VERSION ""

NS_ :

BS_:

BU_:
VAL_TABLE_ OnOff 1 "ON" 0 "OFF" ;

BO_ 1287 dbgGdStatus2: 4 Vector__XXX
 SG_ respNum : 16|16@1+ (1,0) [0|0] "" Vector__XXX
 SG_ reqNum : 0|16@1+ (1,0) [0|0] "" Vector__XXX

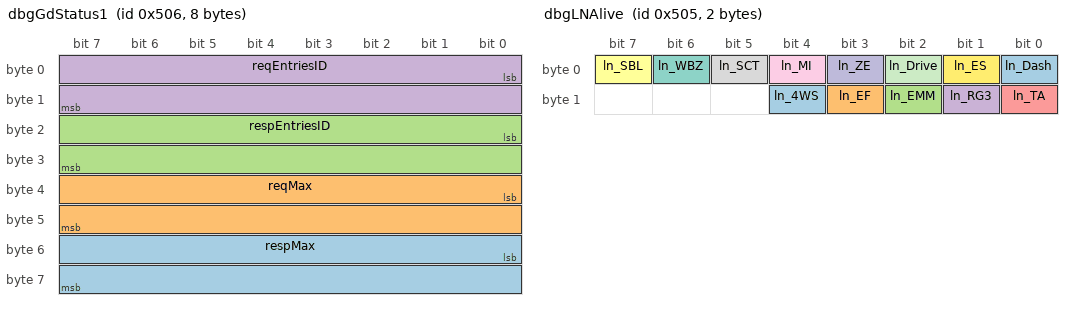
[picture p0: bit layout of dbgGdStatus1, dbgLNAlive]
BO_ 1286 dbgGdStatus1: 8 Vector__XXX
 SG_ respMax : 48|16@1+ (1,0) [0|0] "" Vector__XXX
 SG_ reqMax : 32|16@1+ (1,0) [0|0] "" Vector__XXX
 SG_ respEntriesID : 16|16@1+ (1,0) [0|0] "" Vector__XXX
 SG_ reqEntriesID : 0|16@1+ (1,0) [0|0] "" Vector__XXX

BO_ 291 dbgTime: 4 Vector__XXX
 SG_ keepAlive : 0|32@1+ (0.1,0) [0|0] "[s]" Vector__XXX

BO_ 1285 dbgLNAlive: 2 Vector__XXX
 SG_ ln_4WS : 12|1@1+ (1,0) [0|1] "" Vector__XXX
 SG_ ln_EF : 11|1@1+ (1,0) [0|1] "" Vector__XXX
 SG_ ln_EMM : 10|1@1+ (1,0) [0|1] "" Vector__XXX
 SG_ ln_RG3 : 9|1@1+ (1,0) [0|1] "" Vector__XXX
 SG_ ln_TA : 8|1@1+ (1,0) [0|1] "" Vector__XXX
 SG_ ln_SBL : 7|1@1+ (1,0) [0|1] "" Vector__XXX
 SG_ ln_WBZ : 6|1@1+ (1,0) [0|1] "" Vector__XXX
 SG_ ln_SCT : 5|1@1+ (1,0) [0|1] "" Vector__XXX
 SG_ ln_MI : 4|1@1+ (1,0) [0|1] "" Vector__XXX
 SG_ ln_ZE : 3|1@1+ (1,0) [0|1] "" Vector__XXX
 SG_ ln_Drive : 2|1@1+ (1,0) [0|1] "" Vector__XXX
 SG_ ln_ES : 1|1@1+ (1,0) [0|1] "" Vector__XXX
 SG_ ln_Dash : 0|1@1+ (1,0) [0|1] "" Vector__XXX

BO_ 1284 dbgErrorMessage: 3 Vector__XXX
 SG_ errType : 15|16@0+ (1,0) [0|0] "" Vector__XXX
 SG_ errClass : 0|8@1+ (1,0) [0|0] "" Vector__XXX

BO_ 1283 dbgPxObj2: 8 Vector__XXX
 SG_ MemMinCap : 39|32@0+ (1,0) [0|0] "" Vector__XXX
 SG_ FreeMem : 7|32@0+ (1,0) [0|0] "" Vector__XXX

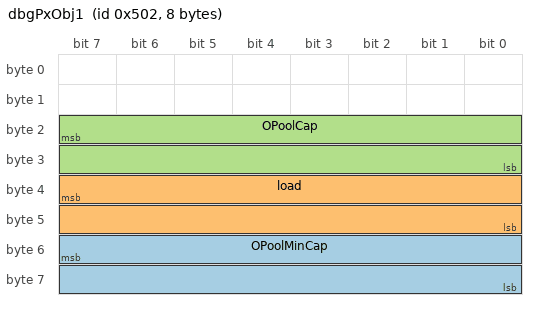
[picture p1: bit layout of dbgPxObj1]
BO_ 1282 dbgPxObj1: 8 Vector__XXX
 SG_ OPoolMinCap : 55|16@0+ (1,0) [0|0] "" Vector__XXX
 SG_ load : 39|16@0+ (1,0) [0|0] "" Vector__XXX
 SG_ OPoolCap : 23|16@0+ (1,0) [0|0] "" Vector__XXX

BA_DEF_ SG_  "SigType" ENUM  "Default","Range","RangeSigned","ASCII","Discrete","Control","ReferencePGN","DTC","StringDelimiter","StringLength","StringLengthControl";
BA_DEF_ SG_  "GenSigEVName" STRING ;
BA_DEF_ SG_  "GenSigILSupport" ENUM  "Yes","No";
BA_DEF_ SG_  "GenSigSendType" ENUM  "Cyclic","OnWrite","reserved","OnChange","reserved","reserved","reserved","NoSigSendType";
BA_DEF_ BO_  "GenMsgILSupport" ENUM  "Yes","No";
BA_DEF_ BU_  "NmStationAddress" INT 0 255;
BA_DEF_ BO_  "GenMsgSendType" ENUM  "cyclic","reserved","cyclicIfActive","reserved","reserved","reserved","reserved","reserved","noMsgSendType";
BA_DEF_ BO_  "GenMsgRequestable" INT 0 1;
BA_DEF_  "DBName" STRING ;
BA_DEF_  "BusType" STRING ;
BA_DEF_  "ProtocolType" STRING ;
BA_DEF_ BO_  "VFrameFormat" ENUM  "StandardCAN","ExtendedCAN","reserved","J1939PG";
BA_DEF_DEF_  "SigType" "Default";
BA_DEF_DEF_  "GenSigEVName" "Env@Nodename_@Signame";
BA_DEF_DEF_  "GenSigILSupport" "Yes";
BA_DEF_DEF_  "GenSigSendType" "NoSigSendType";
BA_DEF_DEF_  "GenMsgILSupport" "Yes";
BA_DEF_DEF_  "NmStationAddress" 254;
BA_DEF_DEF_  "GenMsgSendType" "noMsgSendType";
BA_DEF_DEF_  "GenMsgRequestable" 1;
BA_DEF_DEF_  "DBName" "";
BA_DEF_DEF_  "BusType" "CAN";
BA_DEF_DEF_  "ProtocolType" "J1939";
BA_DEF_DEF_  "VFrameFormat" "J1939PG";
BA_ "DBName" "PxDebug";
BA_ "VFrameFormat" BO_ 1287 0;
BA_ "VFrameFormat" BO_ 1286 0;
BA_ "VFrameFormat" BO_ 291 0;
BA_ "VFrameFormat" BO_ 1285 0;
BA_ "VFrameFormat" BO_ 1284 0;
BA_ "VFrameFormat" BO_ 1283 0;
BA_ "VFrameFormat" BO_ 1282 0;
VAL_ 1285 ln_4WS 1 "ON" 0 "OFF" ;
VAL_ 1285 ln_EF 1 "ON" 0 "OFF" ;
VAL_ 1285 ln_EMM 1 "ON" 0 "OFF" ;
VAL_ 1285 ln_RG3 1 "ON" 0 "OFF" ;
VAL_ 1285 ln_TA 1 "ON" 0 "OFF" ;
VAL_ 1285 ln_SBL 1 "ON" 0 "OFF" ;
VAL_ 1285 ln_WBZ 1 "ON" 0 "OFF" ;
VAL_ 1285 ln_SCT 1 "ON" 0 "OFF" ;
VAL_ 1285 ln_MI 1 "ON" 0 "OFF" ;
VAL_ 1285 ln_ZE 1 "ON" 0 "OFF" ;
VAL_ 1285 ln_Drive 1 "ON" 0 "OFF" ;
VAL_ 1285 ln_ES 1 "ON" 0 "OFF" ;
VAL_ 1285 ln_Dash 1 "ON" 0 "OFF" ;
